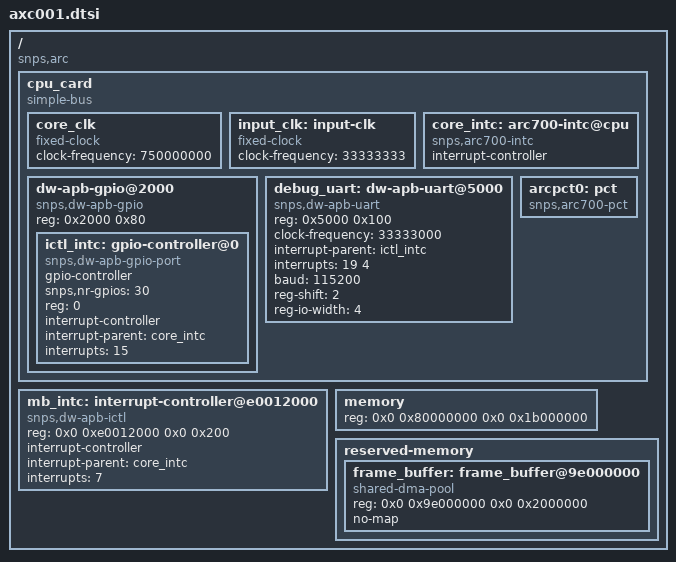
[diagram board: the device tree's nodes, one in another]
/include/ "skeleton.dtsi"
/ {
	compatible = "snps,arc";
	#address-cells = <2>;
	#size-cells = <2>;
	cpu_card {
		compatible = "simple-bus";
		#address-cells = <1>;
		#size-cells = <1>;
		ranges = <0x00000000 0x0 0xf0000000 0x10000000>;
		core_clk: core_clk {
			#clock-cells = <0>;
			compatible = "fixed-clock";
			clock-frequency = <750000000>;
		};
		input_clk: input-clk {
			#clock-cells = <0>;
			compatible = "fixed-clock";
			clock-frequency = <33333333>;
		};
		core_intc: arc700-intc@cpu {
			compatible = "snps,arc700-intc";
			interrupt-controller;
			#interrupt-cells = <1>;
		};
		dw-apb-gpio@2000 {
			compatible = "snps,dw-apb-gpio";
			reg = < 0x2000 0x80 >;
			#address-cells = <1>;
			#size-cells = <0>;
			ictl_intc: gpio-controller@0 {
				compatible = "snps,dw-apb-gpio-port";
				gpio-controller;
				#gpio-cells = <2>;
				snps,nr-gpios = <30>;
				reg = <0>;
				interrupt-controller;
				#interrupt-cells = <2>;
				interrupt-parent = <&core_intc>;
				interrupts = <15>;
			};
		};
		debug_uart: dw-apb-uart@5000 {
			compatible = "snps,dw-apb-uart";
			reg = <0x5000 0x100>;
			clock-frequency = <33333000>;
			interrupt-parent = <&ictl_intc>;
			interrupts = <19 4>;
			baud = <115200>;
			reg-shift = <2>;
			reg-io-width = <4>;
		};
		arcpct0: pct {
			compatible = "snps,arc700-pct";
		};
	};
	mb_intc: interrupt-controller@e0012000 {
		#interrupt-cells = <1>;
		compatible = "snps,dw-apb-ictl";
		reg = < 0x0 0xe0012000 0x0 0x200 >;
		interrupt-controller;
		interrupt-parent = <&core_intc>;
		interrupts = < 7 >;
	};
	memory {
		device_type = "memory";
		reg = <0x0 0x80000000 0x0 0x1b000000>;	 
	};
	reserved-memory {
		#address-cells = <2>;
		#size-cells = <2>;
		ranges;
		frame_buffer: frame_buffer@9e000000 {
			compatible = "shared-dma-pool";
			reg = <0x0 0x9e000000 0x0 0x2000000>;
			no-map;
		};
	};
};
